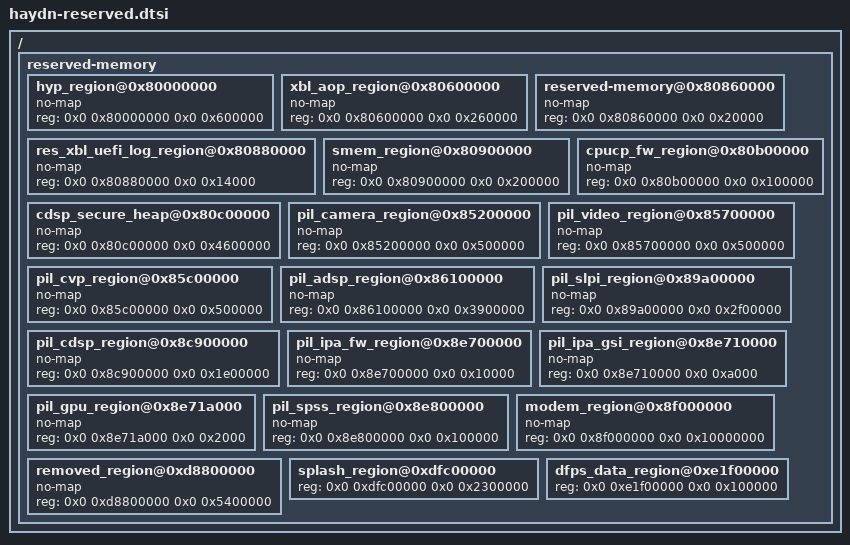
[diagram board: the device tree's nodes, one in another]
// Generated by scripts/gen-reserved-live.py from the phone's own FDT.
//
// 21 regions, 607.7 MiB. Do not edit: change the input and regenerate.
//
// The generator the earlier version of this file used read a DTS, which
// needs dtc. This reads the FDT binary, so the chain is one step shorter:
//
//     adb shell su -c "cat /sys/firmware/fdt" > haydn-fdt.dtb
//     scripts/gen-reserved-live.py haydn-fdt.dtb > dts/haydn-reserved.dtsi
/ {
    reserved-memory {
        hyp_region@0x80000000 {
            no-map;
            reg = <0x0 0x80000000 0x0 0x600000>;
        };
        xbl_aop_region@0x80600000 {
            no-map;
            reg = <0x0 0x80600000 0x0 0x260000>;
        };
        reserved-memory@0x80860000 {
            no-map;
            reg = <0x0 0x80860000 0x0 0x20000>;
        };
        res_xbl_uefi_log_region@0x80880000 {
            no-map;
            reg = <0x0 0x80880000 0x0 0x14000>;
        };
        smem_region@0x80900000 {
            no-map;
            reg = <0x0 0x80900000 0x0 0x200000>;
        };
        cpucp_fw_region@0x80b00000 {
            no-map;
            reg = <0x0 0x80b00000 0x0 0x100000>;
        };
        cdsp_secure_heap@0x80c00000 {
            no-map;
            reg = <0x0 0x80c00000 0x0 0x4600000>;
        };
        pil_camera_region@0x85200000 {
            no-map;
            reg = <0x0 0x85200000 0x0 0x500000>;
        };
        pil_video_region@0x85700000 {
            no-map;
            reg = <0x0 0x85700000 0x0 0x500000>;
        };
        pil_cvp_region@0x85c00000 {
            no-map;
            reg = <0x0 0x85c00000 0x0 0x500000>;
        };
        pil_adsp_region@0x86100000 {
            no-map;
            reg = <0x0 0x86100000 0x0 0x3900000>;
        };
        pil_slpi_region@0x89a00000 {
            no-map;
            reg = <0x0 0x89a00000 0x0 0x2f00000>;
        };
        pil_cdsp_region@0x8c900000 {
            no-map;
            reg = <0x0 0x8c900000 0x0 0x1e00000>;
        };
        pil_ipa_fw_region@0x8e700000 {
            no-map;
            reg = <0x0 0x8e700000 0x0 0x10000>;
        };
        pil_ipa_gsi_region@0x8e710000 {
            no-map;
            reg = <0x0 0x8e710000 0x0 0xa000>;
        };
        pil_gpu_region@0x8e71a000 {
            no-map;
            reg = <0x0 0x8e71a000 0x0 0x2000>;
        };
        pil_spss_region@0x8e800000 {
            no-map;
            reg = <0x0 0x8e800000 0x0 0x100000>;
        };
        modem_region@0x8f000000 {
            no-map;
            reg = <0x0 0x8f000000 0x0 0x10000000>;
        };
        removed_region@0xd8800000 {
            no-map;
            reg = <0x0 0xd8800000 0x0 0x5400000>;
        };
        splash_region@0xdfc00000 {
            reg = <0x0 0xdfc00000 0x0 0x2300000>;
        };
        dfps_data_region@0xe1f00000 {
            reg = <0x0 0xe1f00000 0x0 0x100000>;
        };
    };
};
